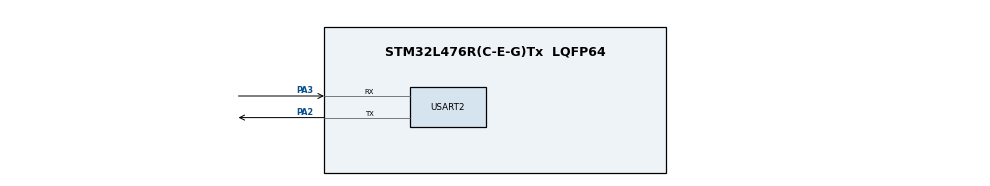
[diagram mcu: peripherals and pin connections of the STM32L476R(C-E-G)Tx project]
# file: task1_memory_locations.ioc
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Mcu.Family=STM32L4
Mcu.Name=STM32L476R(C-E-G)Tx
Mcu.Package=LQFP64
NVIC.PriorityGroup=NVIC_PRIORITYGROUP_4
PA2.Mode=Asynchronous
PA2.Signal=USART2_TX
PA3.Mode=Asynchronous
PA3.Signal=USART2_RX
ProjectManager.HeapSize=0x200
ProjectManager.StackSize=0x400
ProjectManager.TargetToolchain=CMake
RCC.HSE_VALUE=8000000
RCC.HSI_VALUE=16000000
RCC.LSE_VALUE=32768
RCC.MSI_VALUE=4000000
RCC.VCOOutputFreq_Value=32000000
USART2.VirtualMode-Asynchronous=VM_ASYNC
board=custom

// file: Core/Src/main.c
/* USER CODE BEGIN Header */
/**
 ******************************************************************************
 * @file           : main.c
 * @brief          : Main program body
 ******************************************************************************
 * @attention
 *
 * Copyright (c) 2026 STMicroelectronics.
 * All rights reserved.
 *
 * This software is licensed under terms that can be found in the LICENSE file
 * in the root directory of this software component.
 * If no LICENSE file comes with this software, it is provided AS-IS.
 *
 ******************************************************************************
 */
/* USER CODE END Header */
#include "main.h"

/* USER CODE BEGIN Includes */
#include "mem_diag.h"
#include "mem_vars.h"
/* USER CODE END Includes */

UART_HandleTypeDef huart2;

void SystemClock_Config(void);
static void MX_GPIO_Init(void);
static void MX_USART2_UART_Init(void);

int main(void)
{

    /* MCU
     * Configuration--------------------------------------------------------*/

    /* Reset of all peripherals, Initializes the Flash interface and the
     * Systick. */
    HAL_Init();

    /* Configure the system clock */
    SystemClock_Config();

    /* Initialize all configured peripherals */
    MX_GPIO_Init();
    MX_USART2_UART_Init();
    /* USER CODE BEGIN 2 */
    static uint32_t s_mainStaticVar = 0x33333333UL;
    uint32_t autoVar = 0x55555555UL;

    mem_vars_init();

    printAddress("main", (uint32_t)&main);
    printAddress("g_globalVar (global)", (uint32_t)&g_globalVar);
    printAddress("s_fileStaticVar (file-static)",
                 mem_vars_get_file_static_address());
    printAddress("s_mainStaticVar (static in main)",
                 (uint32_t)&s_mainStaticVar);
    printAddress("autoVar (local in main)", (uint32_t)&autoVar);
    printAddress("g_ram2Var (RAM2 section)", mem_vars_get_ram2_address());
    /* USER CODE END 2 */

    /* Infinite loop */
    while (1)
    {

    }
}

void SystemClock_Config(void)
{
    RCC_OscInitTypeDef RCC_OscInitStruct = {0};
    RCC_ClkInitTypeDef RCC_ClkInitStruct = {0};

    /** Configure the main internal regulator output voltage
     */
    if (HAL_PWREx_ControlVoltageScaling(PWR_REGULATOR_VOLTAGE_SCALE1) != HAL_OK)
    {
        Error_Handler();
    }

    /** Initializes the RCC Oscillators according to the specified parameters
     * in the RCC_OscInitTypeDef structure.
     */
    RCC_OscInitStruct.OscillatorType = RCC_OSCILLATORTYPE_MSI;
    RCC_OscInitStruct.MSIState = RCC_MSI_ON;
    RCC_OscInitStruct.MSICalibrationValue = 0;
    RCC_OscInitStruct.MSIClockRange = RCC_MSIRANGE_6;
    RCC_OscInitStruct.PLL.PLLState = RCC_PLL_NONE;
    if (HAL_RCC_OscConfig(&RCC_OscInitStruct) != HAL_OK)
    {
        Error_Handler();
    }

    /** Initializes the CPU, AHB and APB buses clocks
     */
    RCC_ClkInitStruct.ClockType = RCC_CLOCKTYPE_HCLK | RCC_CLOCKTYPE_SYSCLK |
                                  RCC_CLOCKTYPE_PCLK1 | RCC_CLOCKTYPE_PCLK2;
    RCC_ClkInitStruct.SYSCLKSource = RCC_SYSCLKSOURCE_MSI;
    RCC_ClkInitStruct.AHBCLKDivider = RCC_SYSCLK_DIV1;
    RCC_ClkInitStruct.APB1CLKDivider = RCC_HCLK_DIV1;
    RCC_ClkInitStruct.APB2CLKDivider = RCC_HCLK_DIV1;

    if (HAL_RCC_ClockConfig(&RCC_ClkInitStruct, FLASH_LATENCY_0) != HAL_OK)
    {
        Error_Handler();
    }
}

static void MX_USART2_UART_Init(void)
{

    huart2.Instance = USART2;
    huart2.Init.BaudRate = 115200;
    huart2.Init.WordLength = UART_WORDLENGTH_8B;
    huart2.Init.StopBits = UART_STOPBITS_1;
    huart2.Init.Parity = UART_PARITY_NONE;
    huart2.Init.Mode = UART_MODE_TX_RX;
    huart2.Init.HwFlowCtl = UART_HWCONTROL_NONE;
    huart2.Init.OverSampling = UART_OVERSAMPLING_16;
    huart2.Init.OneBitSampling = UART_ONE_BIT_SAMPLE_DISABLE;
    huart2.AdvancedInit.AdvFeatureInit = UART_ADVFEATURE_NO_INIT;
    if (HAL_UART_Init(&huart2) != HAL_OK)
    {
        Error_Handler();
    }
}

static void MX_GPIO_Init(void)
{

    /* GPIO Ports Clock Enable */
    __HAL_RCC_GPIOA_CLK_ENABLE();

}

/* USER CODE BEGIN 4 */
int __io_putchar(int ch)
{
    uint8_t character;

    character = (uint8_t)ch;
    (void)HAL_UART_Transmit(&huart2, &character, 1U, HAL_MAX_DELAY);

    return ch;
}
/* USER CODE END 4 */

void Error_Handler(void)
{
    /* USER CODE BEGIN Error_Handler_Debug */
    /* User can add his own implementation to report the HAL error return state
     */
    __disable_irq();
    while (1)
    {
    }
    /* USER CODE END Error_Handler_Debug */
}
#ifdef USE_FULL_ASSERT
/**
 * @brief  Reports the name of the source file and the source line number
 *         where the assert_param error has occurred.
 * @param  file: pointer to the source file name
 * @param  line: assert_param error line source number
 * @retval None
 */
void assert_failed(uint8_t *file, uint32_t line)
{
    /* USER CODE BEGIN 6 */
    /* User can add his own implementation to report the file name and line
       number, ex: printf("Wrong parameters value: file %s on line %d\r\n",
       file, line) */
    /* USER CODE END 6 */
}
#endif /* USE_FULL_ASSERT */
